# DEBUGSS_WRAP_AXIAP_CFG_0_000700002200h register map
Vendor: Texas Instruments
Peripheral module from a debugger description file (folder am62D).
Registers are 32-bit, read-write, reset 0x0 unless marked. A register's access mark holds for its fields unless they carry their own. Offsets are as the file gives them; lines under a group give offsets from that group; [hi:lo] are bit positions; {n}, {i} and the like mark numbered series; 'fields as' and 'values as' point back to an identical list; <NAME> marks a mode.

## axiap_cfg_0
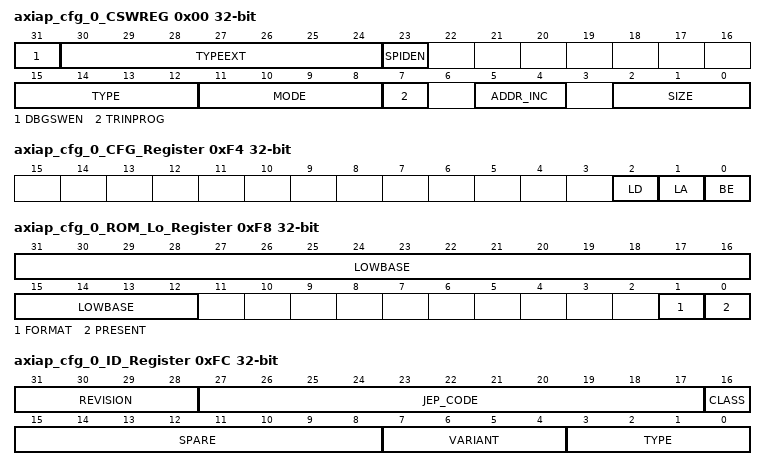
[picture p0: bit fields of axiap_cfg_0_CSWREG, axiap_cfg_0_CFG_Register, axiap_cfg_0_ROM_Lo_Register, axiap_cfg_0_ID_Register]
0x00 axiap_cfg_0_CSWREG access per field — This is the control/status register
  [31] DBGSWEN rw — Indicates whether accesses should treated as application or debug
  [30:24] TYPEEXT rw
  [23] SPIDEN ro — When 1, secure accesses are enabled
  [15:12] TYPE rw — Sets Prot, Type attributes for the access
  [11:8] MODE rw — Sets mode of operation 0000=basic, 0001=Barrier extensions, all other values reserved
  [7] TRINPROG ro — This bit is set to 1 while a transfer is in progress on the connection to the memory system, and is set to 0 while the connection is idle
  [5:4] ADDR_INC rw — Address Auto Increment and packing mode
  [2:0] SIZE ro — This specifies the size of the access For this implementation, the access is always 32 bits [010]
0x04 axiap_cfg_0_TAREGL — This register contains the lower 32-bits of address to write to or read from.
  [31:0] TAL — This register contains the lower 32-bits of address
0x08 axiap_cfg_0_TAREGH — This register contains the upper 32-bits of address to write to or read from.
  [31:0] TAH — This register contains the upper 32-bits of address
0x0C axiap_cfg_0_DRWREG — This register is used to write data to the TA location or read it back from the TA location.
  [31:0] DATA_READ_WRITE_REGISTER — This register is used to read or write data
{0x10+4i} axiap_cfg_0_BD{i}REG (i=0..3) — This register is used to transfer data when doing banked data operations.
  [31:0] BANKED_DATA_{i}_REGISTER — This register is used to transfer data when doing banked data operations
0x20 axiap_cfg_0_MBT_Register — This register sets memory barrier attributes
  [31:0] MEMORY_BARRIER_TRANSFER_REGISTER
0xF0 axiap_cfg_0_ROM_Hi_Register ro — Reading this register returns the AXI ROM Address (63-32).
  [31:0] ROM_HI_REGISTER_ADDRESS — Reading this register returns the upper ROM Address
0xF4 axiap_cfg_0_CFG_Register ro — The CFG register provides information about how the MEM-AP implementation is configured.
  [2] LD — This bit indicates whether the MEM-AP implementation includes the Large Data Extension, that provides support for data items larger than 32-bits, it is 0
  [1] LA — This bit indicates whether the MEM-AP implementation includes the Large Physical Address Extension, that supports physical addresses of more than 32-bits:
  [0] BE — ADIv52 obsoletes support for big-endian MEM-AP, and this bit must RAZ
0xF8 axiap_cfg_0_ROM_Lo_Register ro — Reading this register returns the AXI ROM Address (31:12) .
  [31:12] LOWBASE — Bits 31:12 of the base address
  [1] FORMAT — Base address register format [0]
  [0] PRESENT — This field indicates whether a debug entry is present for this MEM-AP: 0 No debug entry present 1 Debug entry present
0xFC axiap_cfg_0_ID_Register ro — Reading this register returns the ID information for this AP.
  [31:28] REVISION — Device Revision [4]
  [27:17] JEP_CODE — Device JEP Code [0x23B]
  [16] CLASS — Device Class[1] [a memory access port]
  [15:8] SPARE — Spare, returns 0
  [7:4] VARIANT — Device Variant [0]
  [3:0] TYPE — Device Type: 0=JTAG, 1=AHB, 2=APB, 4=AXI [4]
